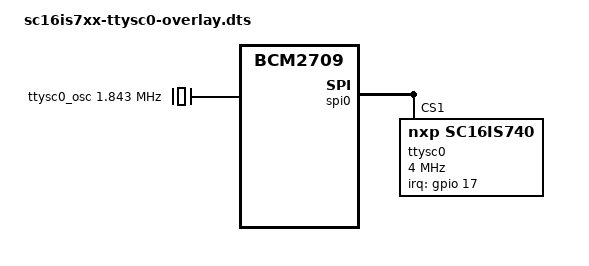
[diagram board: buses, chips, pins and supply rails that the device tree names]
/*
 * Device tree overlay for sc16is740/ttysc0 on spi0.1
 */

/dts-v1/;
/plugin/;

/ {
    compatible = "brcm,bcm2835", "brcm,bcm2836", "brcm,bcm2708", "brcm,bcm2709";
    /* disable spi-dev for spi0.1 */
    fragment@0 {
        target = <&spi0>;
        __overlay__ {
            status = "okay";
            spidev@1{
                status = "disabled";
            };
        };
    };

    /* the interrupt pin of the can-controller */
    fragment@1 {
        target = <&gpio>;
        __overlay__ {
            ttysc0_pins: ttysc0_pins {
                brcm,pins = <17>;
                brcm,function = <0>; /* input */
            };
        };
    };

    /* the clock/oscillator of the can-controller */
    fragment@2 {
        target-path = "/clocks";
        __overlay__ {
            /* external oscillator of sc16is740 on SPI0.1 */
            ttysc0_osc: ttysc0_osc {
                compatible = "fixed-clock";
                #clock-cells = <0>;
                clock-frequency  = <1843200>;
            };
        };
    };

    /* the spi config of the can-controller itself binding everything together */
    fragment@3 {
        target = <&spi0>;
        __overlay__ {
            /* needed to avoid dtc warning */
            #address-cells = <1>;
            #size-cells = <0>;
            ttysc0: sc16is740@1 {
                reg = <1>;
                compatible = "nxp,sc16is740";
                pinctrl-names = "default";
                pinctrl-0 = <&ttysc0_pins>;
                spi-max-frequency = <4000000>;
                interrupt-parent = <&gpio>;
                interrupts = <17 0x8>;
                clocks = <&ttysc0_osc>;
                status = "okay";
            };
        };
    };
    __overrides__ {
        oscillator = <&ttysc0_osc>,"clock-frequency:0";
        spimaxfrequency = <&ttysc0>,"spi-max-frequency:0";
        interrupt = <&ttysc0_pins>,"brcm,pins:0",<&ttysc0>,"interrupts:0";
    };
};
